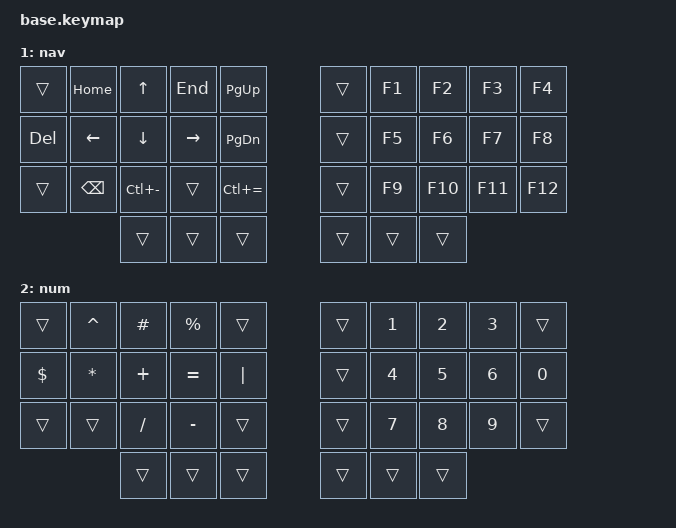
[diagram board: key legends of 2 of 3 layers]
/*
 * Copyright (c) 2020 The ZMK Contributors
 *
 * SPDX-License-Identifier: MIT
 */
 
#include <behaviors.dtsi>
#include <dt-bindings/zmk/keys.h>
#include <dt-bindings/zmk/bt.h>
#include <dt-bindings/zmk/outputs.h>

// Define layer numbers
#define DEF 0
#define NAV 1
#define NUM 2

//Personal includes
#include "../zmk-nodefree-config/helper.h"

/* Global settings */

#define QUICK_TAP_MS 175

&sk {  // sticky-key config
    release-after-ms = <900>;  // release after 0.6s
    quick-release;             // no double capitalization when rolling keys
};

&sl {  // sticky-layer config
    ignore-modifiers;          // allow chording sticky mods & layers
};

&lt {  // layer-tap config
    flavor = "balanced";
    tapping-term-ms = <200>;
    quick-tap-ms = <QUICK_TAP_MS>;
};

/* Homerow mods */

/* use helper macros to define left and right hand keys */
#include "../zmk-nodefree-config/keypos_def/keypos_36keys.h"                // keyposition helpers
#define KEYS_L LT0 LT1 LT2 LT3 LT4 LM0 LM1 LM2 LM3 LM4 LB0 LB1 LB2 LB3 LB4  // left-hand keys
#define KEYS_R RT0 RT1 RT2 RT3 RT4 RM0 RM1 RM2 RM3 RM4 RB0 RB1 RB2 RB3 RB4  // right-hand keys
#define THUMBS LH2 LH1 LH0 RH0 RH1 RH2                                      // thumb keys

/* left-hand HRMs */
ZMK_BEHAVIOR(hml, hold_tap,
    flavor = "balanced";
    tapping-term-ms = <280>;
    quick-tap-ms = <175>;                // repeat on tap-into-hold
    require-prior-idle-ms = <150>;
    bindings = <&kp>, <&kp>;
    hold-trigger-key-positions = <KEYS_R THUMBS>;
    hold-trigger-on-release;             // delay positional check until key-release
)

/* right-hand HRMs */
ZMK_BEHAVIOR(hmr, hold_tap,
    flavor = "balanced";
    tapping-term-ms = <280>;
    quick-tap-ms = <175>;                // repeat on tap-into-hold
    require-prior-idle-ms = <150>;
    bindings = <&kp>, <&kp>;
    hold-trigger-key-positions = <KEYS_L THUMBS>;
    hold-trigger-on-release;             // delay positional check until key-release
)

//Combos

/*                KEY POSITIONS

  ╭─────────────────────╮ ╭─────────────────────╮
  │ LT4 LT3 LT2 LT1 LT0 │ │ RT0 RT1 RT2 RT3 RT4 │
  │ LM4 LM3 LM2 LM1 LM0 │ │ RM0 RM1 RM2 RM3 RM4 │
  │ LB4 LB3 LB2 LB1 LB0 │ │ RB0 RB1 RB2 RB3 RB4 │
  ╰───────╮ LH2 LH1 LH0 │ │ RH0 RH1 RH2 ╭───────╯
          ╰─────────────╯ ╰─────────────╯ */
          
// use require-prior-idle-ms for combos
#undef COMBO_HOOK
#define COMBO_HOOK require-prior-idle-ms = <150>;

#define COMBO_TERM_FAST 18
#define COMBO_TERM_SLOW 30

// make homerow combos tap-only (so HRMs can be chorded instantaneously)
#define HRC_TAB    &hml         LA(LCTRL) TAB
#define HRC_REPEAT &hml_repeat  LS(LCTRL) 0
#define HRC_LPAR   &hmr_lpar_lt RS(LCTRL) 0
#define HRC_RPAR   &hmr_rpar_gt LA(LCTRL) 0

ZMK_COMBO(Save, &kp LC(S), LM1 LM2, ALL, COMBO_TERM_FAST)
ZMK_COMBO(Capsword, &caps_word, LM1 LM2 LM3, ALL, COMBO_TERM_FAST)
ZMK_COMBO(esc, &kp ESC, LT1 LT2, ALL, COMBO_TERM_FAST)
ZMK_COMBO(semicolon, &kp SEMICOLON, RT1 RT2, ALL, COMBO_TERM_FAST)
ZMK_COMBO(colon, &kp COLON, RT1 RT2 RT3, ALL, COMBO_TERM_FAST)
ZMK_COMBO(dot, &kp DOT, RM1 RM2, ALL, COMBO_TERM_FAST)
ZMK_COMBO(comma, &kp COMMA, RM1 RM2 RM3, ALL, COMBO_TERM_FAST)
ZMK_COMBO(par, &par, RB1 RB2, ALL, COMBO_TERM_FAST)
ZMK_COMBO(bracket, &br, RB1 RB2 RB3, ALL, COMBO_TERM_FAST)
ZMK_COMBO(slash, &sla, LB1 LB2, ALL, COMBO_TERM_FAST)
ZMK_COMBO(undo, &kp LC(Z), LB3 LB4, ALL, COMBO_TERM_FAST)

ZMK_BEHAVIOR(qu, tap_dance,
    tapping-term-ms = <200>;
    bindings = <&kp QUESTION>, <&kp EXCLAMATION>;
)

ZMK_BEHAVIOR(z_undo, tap_dance,
    tapping-term-ms = <200>;
    bindings = <&kp Z>, <&kp LC(Z)>;
)

ZMK_BEHAVIOR(ap_qo, tap_dance,
    tapping-term-ms = <200>;
    bindings = <&kp APOSTROPHE>, <&kp DOUBLE_QUOTES>;
)

ZMK_BEHAVIOR(at, tap_dance,
    tapping-term-ms = <200>;
    bindings = <&kp AT_SIGN>, <&kp AMPERSAND>;
)

ZMK_BEHAVIOR(sla, tap_dance,
    tapping-term-ms = <200>;
    bindings = <&kp SLASH>, <&kp BACKSLASH>;
)

ZMK_BEHAVIOR(par, tap_dance,
    tapping-term-ms = <200>;
    bindings = <&kp LPAR>, <&kp RPAR>;
)

ZMK_BEHAVIOR(br, tap_dance,
    tapping-term-ms = <200>;
    bindings = <&kp LEFT_BRACKET>, <&kp RIGHT_BRACKET>;
)

ZMK_BEHAVIOR(hyph, tap_dance,
    tapping-term-ms = <200>;
    bindings = <&kp MINUS>, <&kp UNDERSCORE>, <&kp TILDE>;
)

ZMK_LAYER(base,
// ╭────────────────────────┬────────────────────────┬────────────────────────┬────────────────────────┬────────────────────────╮    ╭────────────────────────┬────────────────────────┬────────────────────────┬───────────────────────┬────────────────────────╮
     &kp Q                    &kp W                    &hml LCTRL(F) F          &hml LCTRL(I)            &hml LCTRL(B) B               &kp J                    &kp L                    &kp U                    &kp Y                    &qu 
// ├────────────────────────┼────────────────────────┼────────────────────────┼────────────────────────┼────────────────────────┤    ├────────────────────────┼────────────────────────┼────────────────────────┼───────────────────────┼────────────────────────┤
     &hml LGUI A              &hml LALT R              &hml LCTRL S             &hml LSHFT T             &kp G                         &kp M                    &hmr RSHFT N             &hmr RCTRL E             &hmr LALT I              &hmr RGUI O
// ├────────────────────────┼────────────────────────┼────────────────────────┼────────────────────────┼────────────────────────┤    ├────────────────────────┼────────────────────────┼────────────────────────┼───────────────────────┼────────────────────────┤
     &z_undo                  &hml LCTRL(X) X          &hml LCTRL(C) C          &hml LCTRL(V) D          &kp V                         &kp K                    &kp H                    &ap_qo                   &at                      &hyph
// ╰────────────────────────┴────────────────────────┴────────────────────────┴────────────────────────┼────────────────────────┤    ├────────────────────────┼────────────────────────┼────────────────────────┴───────────────────────┴────────────────────────╯
                                                       &lt NUM DEL                  &lt NAV TAB          &kp SPACE                     &kp BACKSPACE            &kp ENTER                &kp DEL
//                                                   ╰────────────────────────┴────────────────────────┴────────────────────────╯    ╰────────────────────────┴────────────────────────┴────────────────────────╯
)

ZMK_LAYER(nav,            
// ╭────────────────────────┬────────────────────────┬────────────────────────┬────────────────────────┬────────────────────────╮    ╭────────────────────────┬────────────────────────┬────────────────────────┬───────────────────────┬────────────────────────╮
     &trans                   &kp HOME                 &kp UP                   &kp END                  &kp PAGE_UP                   &trans                    &kp F1                   &kp F2                  &kp F3                   &kp F4
// ├────────────────────────┼────────────────────────┼────────────────────────┼────────────────────────┼────────────────────────┤    ├────────────────────────┼────────────────────────┼────────────────────────┼───────────────────────┼────────────────────────┤
     &kp DEL                  &kp LEFT                 &kp DOWN                 &kp RIGHT                &kp PAGE_DOWN                 &trans                    &kp F5                   &kp F6                  &kp F7                   &kp F8
// ├────────────────────────┼────────────────────────┼────────────────────────┼────────────────────────┼────────────────────────┤    ├────────────────────────┼────────────────────────┼────────────────────────┼───────────────────────┼────────────────────────┤
     &trans                   &kp BACKSPACE            &kp LC(MINUS)            &trans                   &kp LC(EQUAL)                 &trans                    &kp F9                   &kp F10                 &kp F11                  &kp F12
// ╰────────────────────────┴────────────────────────┴────────────────────────┼────────────────────────┼────────────────────────┤    ├────────────────────────┼────────────────────────┼────────────────────────┴───────────────────────┴────────────────────────╯
                                                       &trans                   &trans                   &trans                        &trans                    &trans                   &trans 
//                                                   ╰────────────────────────┴────────────────────────┴────────────────────────╯    ╰────────────────────────┴────────────────────────┴────────────────────────╯
)

ZMK_LAYER(num,
// ╭────────────────────────┬────────────────────────┬────────────────────────┬────────────────────────┬────────────────────────╮    ╭────────────────────────┬────────────────────────┬────────────────────────┬───────────────────────┬────────────────────────╮
     &trans                   &kp CARET                &kp HASH                 &kp PERCENT              &trans                        &trans                    &kp N1                   &kp N2                  &kp N3                   &trans
// ├────────────────────────┼────────────────────────┼────────────────────────┼────────────────────────┼────────────────────────┤    ├────────────────────────┼────────────────────────┼────────────────────────┼───────────────────────┼────────────────────────┤
     &kp DOLLAR               &kp STAR                 &kp PLUS                 &kp EQUAL                &kp PIPE                      &trans                    &kp N4                   &kp N5                  &kp N6                   &kp N0
// ├────────────────────────┼────────────────────────┼────────────────────────┼────────────────────────┼────────────────────────┤    ├────────────────────────┼────────────────────────┼────────────────────────┼───────────────────────┼────────────────────────┤
     &trans                   &trans                   &kp SLASH                &kp MINUS                &trans                        &trans                    &kp N7                   &kp N8                  &kp N9                   &trans
// ╰────────────────────────┴────────────────────────┴────────────────────────┼────────────────────────┼────────────────────────┤    ├────────────────────────┼────────────────────────┼────────────────────────┴───────────────────────┴────────────────────────╯
                                                       &trans                   &trans                   &trans                        &trans                    &trans                   &trans 
//                                                   ╰────────────────────────┴────────────────────────┴────────────────────────╯    ╰────────────────────────┴────────────────────────┴────────────────────────╯
)
